# AT90CAN64 register map
Vendor: Atmel; File version: 1.0
CPU: other r0p0, little endian, no MPU, no FPU, 4 interrupt priority bits
Registers are 8-bit, read-write, reset 0x0 unless marked. A register's access mark holds for its fields unless they carry their own. Offsets are from the block's base; [hi:lo] are bit positions; {n}, {i} and the like mark numbered series; 'fields as' and 'values as' point back to an identical list.

## BOOT_LOAD — Bootloader
Base 0x00000057
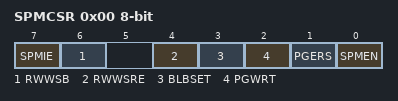
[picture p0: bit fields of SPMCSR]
0x00 SPMCSR — Store Program Memory Control Register
  [7] SPMIE — SPM Interrupt Enable
  [6] RWWSB — Read While Write Section Busy
  [4] RWWSRE — Read While Write section read enable
  [3] BLBSET — Boot Lock Bit Set
  [2] PGWRT — Page Write
  [1] PGERS — Page Erase
  [0] SPMEN — Store Program Memory Enable

## CPU — CPU Registers
Base 0x0000003E
0x00 GPIOR0 — General Purpose IO Register 0
0x0C GPIOR1 — General Purpose IO Register 1
0x0D GPIOR2 — General Purpose IO Register 2
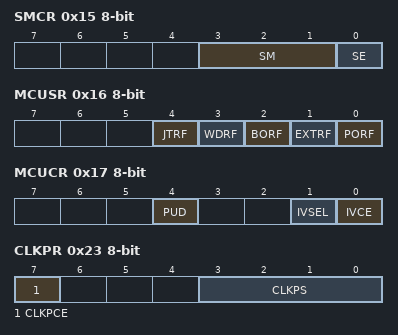
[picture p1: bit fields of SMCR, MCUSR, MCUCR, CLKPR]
0x15 SMCR — Sleep Mode Control Register
  [3:1] SM — Sleep Mode Select bits
    0=IDLE; 1=ADC (ADC Noise Reduction (If Available)); 2=PDOWN (Power Down); 3=PSAVE (Power Save); 6=STDBY (Standby)
  [0] SE — Sleep Enable
0x16 MCUSR — MCU Status Register
  [4] JTRF — JTAG Reset Flag
  [3] WDRF — Watchdog Reset Flag
  [2] BORF — Brown-out Reset Flag
  [1] EXTRF — External Reset Flag
  [0] PORF — Power-on reset flag
0x17 MCUCR — MCU Control Register
  [4] PUD — Pull-up disable
  [1] IVSEL — Interrupt Vector Select
  [0] IVCE — Interrupt Vector Change Enable
0x1D RAMPZ — RAM Page Z Select Register - Not used.
  [0] RAMPZ0 — RAM Page Z Select Register Bit 0
0x23 CLKPR — Clock Prescale Register
  [7] CLKPCE
  [3:0] CLKPS
    0=1; 1=2; 2=4; 3=8; 4=16; 5=32; 6=64; 7=128; 8=256
0x28 OSCCAL — Oscillator Calibration Value
  [7:0] OSCCAL — Oscillator Calibration
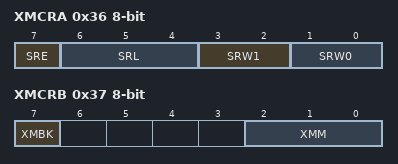
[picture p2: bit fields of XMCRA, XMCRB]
0x36 XMCRA — External Memory Control Register A
  [7] SRE — External SRAM Enable
  [6:4] SRL — Wait state page limit
    0=LS = N/A, US = 0x1100 - 0xFFFF; 1=LS = XMEMSTART - 0x1FFF, US = 0x2000 - 0xFFFF; 2=LS = XMEMSTART - 0x3FFF, US = 0x4000 - 0xFFFF; 3=LS = XMEMSTART - 0x5FFF, US = 0x6000 - 0xFFFF; 4=LS = XMEMSTART - 0x7FFF, US = 0x8000 - 0xFFFF; 5=LS = XMEMSTART - 0x9FFF, US = 0xA000 - 0xFFFF; 6=LS = XMEMSTART - 0xBFFF, US = 0xC000 - 0xFFFF; 7=LS = XMEMSTART - 0xDFFF, US = 0xE000 - 0xFFFF
  [3:2] SRW1 — Wait state select bit upper page
    0=No wait-states; 1=Wait one cycle during read/write strobe; 2=Wait two cycles during read/write strobe; 3=Wait two cycles during read/write and wait one cycle before driving out new address
  [1:0] SRW0 — Wait state select bit lower page
    values as SRW1
0x37 XMCRB — External Memory Control Register B
  [7] XMBK — External Memory Bus Keeper Enable
  [2:0] XMM — External Memory High Mask

## EEPROM
Base 0x0000003F
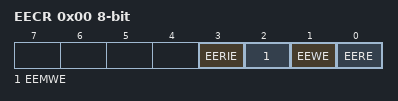
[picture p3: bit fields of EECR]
0x00 EECR — EEPROM Control Register
  [3] EERIE — EEPROM Ready Interrupt Enable
  [2] EEMWE — EEPROM Master Write Enable
  [1] EEWE — EEPROM Write Enable
  [0] EERE — EEPROM Read Enable
0x01 EEDR — EEPROM Data Register
  [7:0] EEDR — EEPROM Data bits
0x02 EEAR 16-bit (reset mask 0xFF) — EEPROM Read/Write Access Bytes - Only bit 10..8 are used in AT90CAN64 - Only bit 9..8 are used in AT90CAN32
  [11:0] EEAR — EEPROM Address bits

## EXINT — External Interrupts
Base 0x0000003C
0x00 EIFR — External Interrupt Flag Register
  [7:0] INTF — External Interrupt Flags
0x01 EIMSK — External Interrupt Mask Register
  [7:0] INT — External Interrupt Request 7 Enable
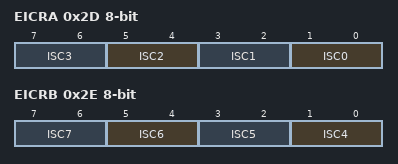
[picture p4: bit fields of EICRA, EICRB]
0x2D EICRA — External Interrupt Control Register A
  [all] fields
    0=Low Level of INTX; 1=Any Logical Change of INTX; 2=Falling Edge of INTX; 3=Rising Edge of INTX
  [2n+1:2n] ISC{n} (n=0..3) — External Interrupt Sense Control Bit
0x2E EICRB — External Interrupt Control Register B
  [all] fields
    values as the fields of EICRA
  [2n-7:2n-8] ISC{n} (n=4..7) — External Interrupt 7-4 Sense Control Bit

## JTAG — JTAG Interface
Base 0x00000051
0x00 OCDR — On-Chip Debug Related Register in I/O Memory
0x03 MCUSR — MCU Status Register
  [4] JTRF — JTAG Reset Flag
0x04 MCUCR — MCU Control Register
  [7] JTD — JTAG Interface Disable
